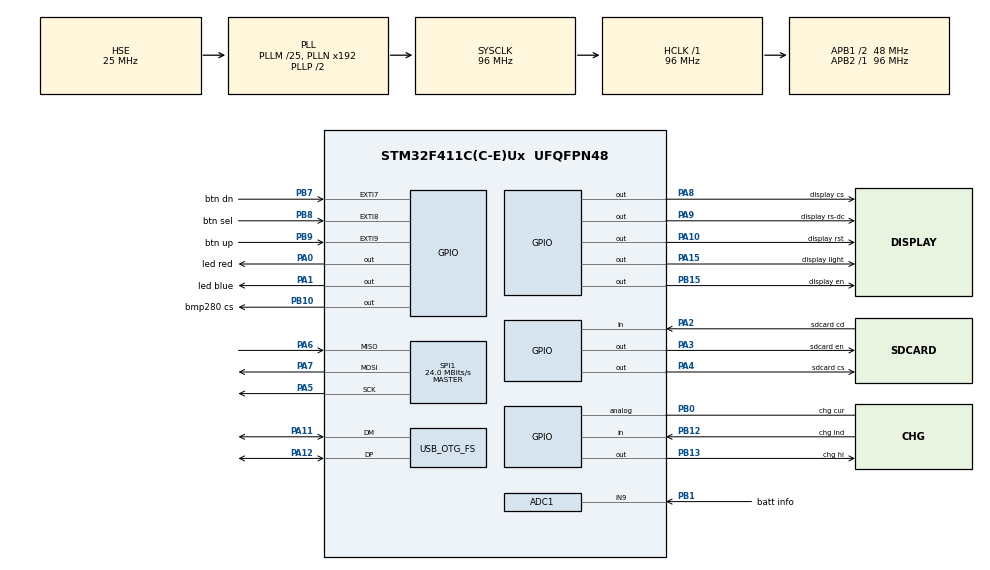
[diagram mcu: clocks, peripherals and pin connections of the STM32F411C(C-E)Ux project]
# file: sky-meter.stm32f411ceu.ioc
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ADC1.Channel-0\#ChannelRegularConversion=ADC_CHANNEL_9
ADC1.NbrOfConversionFlag=1
ADC1.Rank-0\#ChannelRegularConversion=1
ADC1.SamplingTime-0\#ChannelRegularConversion=ADC_SAMPLETIME_3CYCLES
ADC1.master=1
Mcu.Family=STM32F4
Mcu.Name=STM32F411C(C-E)Ux
Mcu.Package=UFQFPN48
NVIC.EXTI9_5_IRQn=true\:0\:0\:false\:false\:true\:true\:true\:true
NVIC.OTG_FS_IRQn=true\:0\:0\:false\:false\:true\:false\:true\:true
NVIC.PriorityGroup=NVIC_PRIORITYGROUP_4
NVIC.RTC_WKUP_IRQn=true\:0\:0\:false\:false\:true\:true\:true\:true
PA0-WKUP.GPIO_Label=led red
PA0-WKUP.Signal=GPIO_Output
PA1.GPIO_Label=led blue
PA1.Signal=GPIO_Output
PA10.GPIO_Label=display rst
PA10.Signal=GPIO_Output
PA11.Mode=Device_Only
PA11.Signal=USB_OTG_FS_DM
PA12.Mode=Device_Only
PA12.Signal=USB_OTG_FS_DP
PA15.GPIO_Label=display light
PA15.Signal=GPIO_Output
PA2.GPIO_Label=sdcard cd
PA2.GPIO_PuPd=GPIO_PULLUP
PA2.Signal=GPIO_Input
PA3.GPIO_Label=sdcard en
PA3.PinState=GPIO_PIN_SET
PA3.Signal=GPIO_Output
PA4.GPIO_Label=sdcard cs
PA4.PinState=GPIO_PIN_SET
PA4.Signal=GPIO_Output
PA5.Mode=Full_Duplex_Master
PA5.Signal=SPI1_SCK
PA6.Mode=Full_Duplex_Master
PA6.Signal=SPI1_MISO
PA7.Mode=Full_Duplex_Master
PA7.Signal=SPI1_MOSI
PA8.GPIO_Label=display cs
PA8.PinState=GPIO_PIN_SET
PA8.Signal=GPIO_Output
PA9.GPIO_Label=display rs-dc
PA9.Signal=GPIO_Output
PB0.GPIO_Label=chg cur
PB0.Signal=GPIO_Analog
PB1.GPIO_Label=batt info
PB1.Signal=ADCx_IN9
PB10.GPIO_Label=bmp280 cs
PB10.PinState=GPIO_PIN_SET
PB10.Signal=GPIO_Output
PB12.GPIO_Label=chg ind
PB12.GPIO_PuPd=GPIO_PULLUP
PB12.Signal=GPIO_Input
PB13.GPIO_Label=chg hi
PB13.Signal=GPIO_Output
PB15.GPIO_Label=display en
PB15.PinState=GPIO_PIN_SET
PB15.Signal=GPIO_Output
PB7.GPIO_Label=btn dn
PB7.GPIO_ModeDefaultEXTI=GPIO_MODE_IT_RISING_FALLING
PB7.Signal=GPXTI7
PB8.GPIO_Label=btn sel
PB8.GPIO_ModeDefaultEXTI=GPIO_MODE_IT_RISING_FALLING
PB8.Signal=GPXTI8
PB9.GPIO_Label=btn up
PB9.GPIO_ModeDefaultEXTI=GPIO_MODE_IT_RISING_FALLING
PB9.Signal=GPXTI9
PC14-OSC32_IN.Mode=LSE-External-Oscillator
PC14-OSC32_IN.Signal=RCC_OSC32_IN
PC15-OSC32_OUT.Mode=LSE-External-Oscillator
PC15-OSC32_OUT.Signal=RCC_OSC32_OUT
PH0\ -\ OSC_IN.Mode=HSE-External-Oscillator
PH0\ -\ OSC_IN.Signal=RCC_OSC_IN
PH1\ -\ OSC_OUT.Mode=HSE-External-Oscillator
PH1\ -\ OSC_OUT.Signal=RCC_OSC_OUT
ProjectManager.HeapSize=0x200
ProjectManager.StackSize=0x400
ProjectManager.TargetToolchain=Makefile
RCC.48MHZClocksFreq_Value=48000000
RCC.AHBFreq_Value=96000000
RCC.APB1CLKDivider=RCC_HCLK_DIV2
RCC.APB1Freq_Value=48000000
RCC.APB1TimFreq_Value=96000000
RCC.APB2Freq_Value=96000000
RCC.APB2TimFreq_Value=96000000
RCC.CodegenConfigPeriph=true
RCC.CortexFreq_Value=96000000
RCC.HCLKFreq_Value=96000000
RCC.HSE_VALUE=25000000
RCC.HSI_VALUE=16000000
RCC.LSE_Drive_Capability=RCC_LSEDRIVE_LOW
RCC.LSE_Drive_CapabilityArg=RCC_LSEDRIVE_LOW
RCC.PLLM=25
RCC.PWR_Regulator_Voltage_Scale=PWR_REGULATOR_VOLTAGE_SCALE1
RCC.RCC_RTC_Clock_Source=RCC_RTCCLKSOURCE_LSE
RCC.RCC_RTC_Clock_SourceVirtual=RCC_RTCCLKSOURCE_LSE
RCC.SYSCLKFreq_VALUE=96000000
RCC.SYSCLKSource=RCC_SYSCLKSOURCE_PLLCLK
RCC.VCOOutputFreq_Value=192000000
RTC.Format=RTC_FORMAT_BIN
SH.ADCx_IN9.0=ADC1_IN9,IN9
SPI1.BaudRatePrescaler=SPI_BAUDRATEPRESCALER_4
SPI1.CalculateBaudRate=24.0 MBits/s
SPI1.Direction=SPI_DIRECTION_2LINES
SPI1.Mode=SPI_MODE_MASTER
SPI1.VirtualType=VM_MASTER
USB_DEVICE.CLASS_NAME_FS=CDC
USB_DEVICE.MANUFACTURER_STRING=sky
USB_DEVICE.PRODUCT_STRING_CDC_FS=sky-meter
USB_DEVICE.VirtualMode=Cdc
USB_DEVICE.VirtualModeFS=Cdc_FS
USB_OTG_FS.VirtualMode=Device_Only
VP_RTC_VS_RTC_Activate.Mode=RTC_Enabled
VP_RTC_VS_RTC_Calendar.Mode=RTC_Calendar
VP_RTC_VS_RTC_WakeUp_intern.Mode=WakeUp
VP_USB_DEVICE_VS_USB_DEVICE_CDC_FS.Mode=CDC_FS
board=custom

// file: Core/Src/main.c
/* USER CODE BEGIN Header */
/**
  ******************************************************************************
  * @file           : main.c
  * @brief          : Main program body
  ******************************************************************************
  * @attention
  *
  * Copyright (c) 2024 STMicroelectronics.
  * All rights reserved.
  *
  * This software is licensed under terms that can be found in the LICENSE file
  * in the root directory of this software component.
  * If no LICENSE file comes with this software, it is provided AS-IS.
  *
  ******************************************************************************
  */
/* USER CODE END Header */
#include "main.h"
#include "usb_device.h"

/* USER CODE BEGIN Includes */
#include "../../source/sys/init.h"
#include "../../source/sys/power.h"
/* USER CODE END Includes */

ADC_HandleTypeDef hadc1;

RTC_HandleTypeDef hrtc;

SPI_HandleTypeDef hspi1;

void SystemClock_Config(void);
static void MX_GPIO_Init(void);
static void MX_RTC_Init(void);
static void MX_ADC1_Init(void);
static void MX_SPI1_Init(void);

/* USER CODE BEGIN 0 */
void adcinit() {
    MX_ADC1_Init();
}
/* USER CODE END 0 */

int main(void)
{

  /* MCU Configuration--------------------------------------------------------*/

  /* Reset of all peripherals, Initializes the Flash interface and the Systick. */
  HAL_Init();

  /* Configure the system clock */
  SystemClock_Config();

  /* USER CODE BEGIN SysInit */

    pwr_preinit();

  /* USER CODE END SysInit */

  /* Initialize all configured peripherals */
  MX_GPIO_Init();
  MX_RTC_Init();
  MX_ADC1_Init();
  MX_SPI1_Init();
  MX_USB_DEVICE_Init();
  /* USER CODE BEGIN 2 */

    init_full();

  /* USER CODE END 2 */

  /* Infinite loop */
  while (1)
  {

    /* USER CODE BEGIN 3 */

    pwr_tick();

  }
  /* USER CODE END 3 */
}

void SystemClock_Config(void)
{
  RCC_OscInitTypeDef RCC_OscInitStruct = {0};
  RCC_ClkInitTypeDef RCC_ClkInitStruct = {0};

  /** Configure the main internal regulator output voltage
  */
  __HAL_RCC_PWR_CLK_ENABLE();
  __HAL_PWR_VOLTAGESCALING_CONFIG(PWR_REGULATOR_VOLTAGE_SCALE1);

  /** Initializes the RCC Oscillators according to the specified parameters
  * in the RCC_OscInitTypeDef structure.
  */
  RCC_OscInitStruct.OscillatorType = RCC_OSCILLATORTYPE_HSE|RCC_OSCILLATORTYPE_LSE;
  RCC_OscInitStruct.HSEState = RCC_HSE_ON;
  RCC_OscInitStruct.LSEState = RCC_LSE_ON;
  RCC_OscInitStruct.PLL.PLLState = RCC_PLL_ON;
  RCC_OscInitStruct.PLL.PLLSource = RCC_PLLSOURCE_HSE;
  RCC_OscInitStruct.PLL.PLLM = 25;
  RCC_OscInitStruct.PLL.PLLN = 192;
  RCC_OscInitStruct.PLL.PLLP = RCC_PLLP_DIV2;
  RCC_OscInitStruct.PLL.PLLQ = 4;
  if (HAL_RCC_OscConfig(&RCC_OscInitStruct) != HAL_OK)
  {
    Error_Handler();
  }

  /** Initializes the CPU, AHB and APB buses clocks
  */
  RCC_ClkInitStruct.ClockType = RCC_CLOCKTYPE_HCLK|RCC_CLOCKTYPE_SYSCLK
                              |RCC_CLOCKTYPE_PCLK1|RCC_CLOCKTYPE_PCLK2;
  RCC_ClkInitStruct.SYSCLKSource = RCC_SYSCLKSOURCE_PLLCLK;
  RCC_ClkInitStruct.AHBCLKDivider = RCC_SYSCLK_DIV1;
  RCC_ClkInitStruct.APB1CLKDivider = RCC_HCLK_DIV2;
  RCC_ClkInitStruct.APB2CLKDivider = RCC_HCLK_DIV1;

  if (HAL_RCC_ClockConfig(&RCC_ClkInitStruct, FLASH_LATENCY_3) != HAL_OK)
  {
    Error_Handler();
  }
}

static void MX_ADC1_Init(void)
{

  ADC_ChannelConfTypeDef sConfig = {0};

  /** Configure the global features of the ADC (Clock, Resolution, Data Alignment and number of conversion)
  */
  hadc1.Instance = ADC1;
  hadc1.Init.ClockPrescaler = ADC_CLOCK_SYNC_PCLK_DIV4;
  hadc1.Init.Resolution = ADC_RESOLUTION_12B;
  hadc1.Init.ScanConvMode = DISABLE;
  hadc1.Init.ContinuousConvMode = DISABLE;
  hadc1.Init.DiscontinuousConvMode = DISABLE;
  hadc1.Init.ExternalTrigConvEdge = ADC_EXTERNALTRIGCONVEDGE_NONE;
  hadc1.Init.ExternalTrigConv = ADC_SOFTWARE_START;
  hadc1.Init.DataAlign = ADC_DATAALIGN_RIGHT;
  hadc1.Init.NbrOfConversion = 1;
  hadc1.Init.DMAContinuousRequests = DISABLE;
  hadc1.Init.EOCSelection = ADC_EOC_SINGLE_CONV;
  if (HAL_ADC_Init(&hadc1) != HAL_OK)
  {
    Error_Handler();
  }

  /** Configure for the selected ADC regular channel its corresponding rank in the sequencer and its sample time.
  */
  sConfig.Channel = ADC_CHANNEL_9;
  sConfig.Rank = 1;
  sConfig.SamplingTime = ADC_SAMPLETIME_3CYCLES;
  if (HAL_ADC_ConfigChannel(&hadc1, &sConfig) != HAL_OK)
  {
    Error_Handler();
  }

}

static void MX_RTC_Init(void)
{

  RTC_TimeTypeDef sTime = {0};
  RTC_DateTypeDef sDate = {0};

  /** Initialize RTC Only
  */
  hrtc.Instance = RTC;
  hrtc.Init.HourFormat = RTC_HOURFORMAT_24;
  hrtc.Init.AsynchPrediv = 127;
  hrtc.Init.SynchPrediv = 255;
  hrtc.Init.OutPut = RTC_OUTPUT_DISABLE;
  hrtc.Init.OutPutPolarity = RTC_OUTPUT_POLARITY_HIGH;
  hrtc.Init.OutPutType = RTC_OUTPUT_TYPE_OPENDRAIN;
  if (HAL_RTC_Init(&hrtc) != HAL_OK)
  {
    Error_Handler();
  }

  /* USER CODE BEGIN Check_RTC_BKUP */
  return;

  /* USER CODE END Check_RTC_BKUP */

  /** Initialize RTC and set the Time and Date
  */
  sTime.Hours = 0;
  sTime.Minutes = 0;
  sTime.Seconds = 0;
  sTime.DayLightSaving = RTC_DAYLIGHTSAVING_NONE;
  sTime.StoreOperation = RTC_STOREOPERATION_RESET;
  if (HAL_RTC_SetTime(&hrtc, &sTime, RTC_FORMAT_BIN) != HAL_OK)
  {
    Error_Handler();
  }
  sDate.WeekDay = RTC_WEEKDAY_MONDAY;
  sDate.Month = RTC_MONTH_JANUARY;
  sDate.Date = 1;
  sDate.Year = 0;

  if (HAL_RTC_SetDate(&hrtc, &sDate, RTC_FORMAT_BIN) != HAL_OK)
  {
    Error_Handler();
  }

  /** Enable the WakeUp
  */
  if (HAL_RTCEx_SetWakeUpTimer_IT(&hrtc, 0, RTC_WAKEUPCLOCK_RTCCLK_DIV16) != HAL_OK)
  {
    Error_Handler();
  }

}

static void MX_SPI1_Init(void)
{

  /* SPI1 parameter configuration*/
  hspi1.Instance = SPI1;
  hspi1.Init.Mode = SPI_MODE_MASTER;
  hspi1.Init.Direction = SPI_DIRECTION_2LINES;
  hspi1.Init.DataSize = SPI_DATASIZE_8BIT;
  hspi1.Init.CLKPolarity = SPI_POLARITY_LOW;
  hspi1.Init.CLKPhase = SPI_PHASE_1EDGE;
  hspi1.Init.NSS = SPI_NSS_SOFT;
  hspi1.Init.BaudRatePrescaler = SPI_BAUDRATEPRESCALER_4;
  hspi1.Init.FirstBit = SPI_FIRSTBIT_MSB;
  hspi1.Init.TIMode = SPI_TIMODE_DISABLE;
  hspi1.Init.CRCCalculation = SPI_CRCCALCULATION_DISABLE;
  hspi1.Init.CRCPolynomial = 10;
  if (HAL_SPI_Init(&hspi1) != HAL_OK)
  {
    Error_Handler();
  }

}

static void MX_GPIO_Init(void)
{
  GPIO_InitTypeDef GPIO_InitStruct = {0};

  /* GPIO Ports Clock Enable */
  __HAL_RCC_GPIOC_CLK_ENABLE();
  __HAL_RCC_GPIOH_CLK_ENABLE();
  __HAL_RCC_GPIOA_CLK_ENABLE();
  __HAL_RCC_GPIOB_CLK_ENABLE();

  /*Configure GPIO pin Output Level */
  HAL_GPIO_WritePin(GPIOA, led_red_Pin|led_blue_Pin|display_rs_dc_Pin|display_rst_Pin
                          |display_light_Pin, GPIO_PIN_RESET);

  /*Configure GPIO pin Output Level */
  HAL_GPIO_WritePin(GPIOA, sdcard_en_Pin|sdcard_cs_Pin|display_cs_Pin, GPIO_PIN_SET);

  /*Configure GPIO pin Output Level */
  HAL_GPIO_WritePin(GPIOB, bmp280_cs_Pin|display_en_Pin, GPIO_PIN_SET);

  /*Configure GPIO pin Output Level */
  HAL_GPIO_WritePin(chg_hi_GPIO_Port, chg_hi_Pin, GPIO_PIN_RESET);

  /*Configure GPIO pins : led_red_Pin led_blue_Pin sdcard_en_Pin sdcard_cs_Pin
                           display_cs_Pin display_rs_dc_Pin display_rst_Pin display_light_Pin */
  GPIO_InitStruct.Pin = led_red_Pin|led_blue_Pin|sdcard_en_Pin|sdcard_cs_Pin
                          |display_cs_Pin|display_rs_dc_Pin|display_rst_Pin|display_light_Pin;
  GPIO_InitStruct.Mode = GPIO_MODE_OUTPUT_PP;
  GPIO_InitStruct.Pull = GPIO_NOPULL;
  GPIO_InitStruct.Speed = GPIO_SPEED_FREQ_LOW;
  HAL_GPIO_Init(GPIOA, &GPIO_InitStruct);

  /*Configure GPIO pin : sdcard_cd_Pin */
  GPIO_InitStruct.Pin = sdcard_cd_Pin;
  GPIO_InitStruct.Mode = GPIO_MODE_INPUT;
  GPIO_InitStruct.Pull = GPIO_PULLUP;
  HAL_GPIO_Init(sdcard_cd_GPIO_Port, &GPIO_InitStruct);

  /*Configure GPIO pin : chg_cur_Pin */
  GPIO_InitStruct.Pin = chg_cur_Pin;
  GPIO_InitStruct.Mode = GPIO_MODE_ANALOG;
  GPIO_InitStruct.Pull = GPIO_NOPULL;
  HAL_GPIO_Init(chg_cur_GPIO_Port, &GPIO_InitStruct);

  /*Configure GPIO pins : bmp280_cs_Pin chg_hi_Pin display_en_Pin */
  GPIO_InitStruct.Pin = bmp280_cs_Pin|chg_hi_Pin|display_en_Pin;
  GPIO_InitStruct.Mode = GPIO_MODE_OUTPUT_PP;
  GPIO_InitStruct.Pull = GPIO_NOPULL;
  GPIO_InitStruct.Speed = GPIO_SPEED_FREQ_LOW;
  HAL_GPIO_Init(GPIOB, &GPIO_InitStruct);

  /*Configure GPIO pin : chg_ind_Pin */
  GPIO_InitStruct.Pin = chg_ind_Pin;
  GPIO_InitStruct.Mode = GPIO_MODE_INPUT;
  GPIO_InitStruct.Pull = GPIO_PULLUP;
  HAL_GPIO_Init(chg_ind_GPIO_Port, &GPIO_InitStruct);

  /*Configure GPIO pins : btn_dn_Pin btn_sel_Pin btn_up_Pin */
  GPIO_InitStruct.Pin = btn_dn_Pin|btn_sel_Pin|btn_up_Pin;
  GPIO_InitStruct.Mode = GPIO_MODE_IT_RISING_FALLING;
  GPIO_InitStruct.Pull = GPIO_NOPULL;
  HAL_GPIO_Init(GPIOB, &GPIO_InitStruct);

  /* EXTI interrupt init*/
  HAL_NVIC_SetPriority(EXTI9_5_IRQn, 0, 0);
  HAL_NVIC_EnableIRQ(EXTI9_5_IRQn);

}

void Error_Handler(void)
{
  __disable_irq();
  while (1)
  {
  }
}
